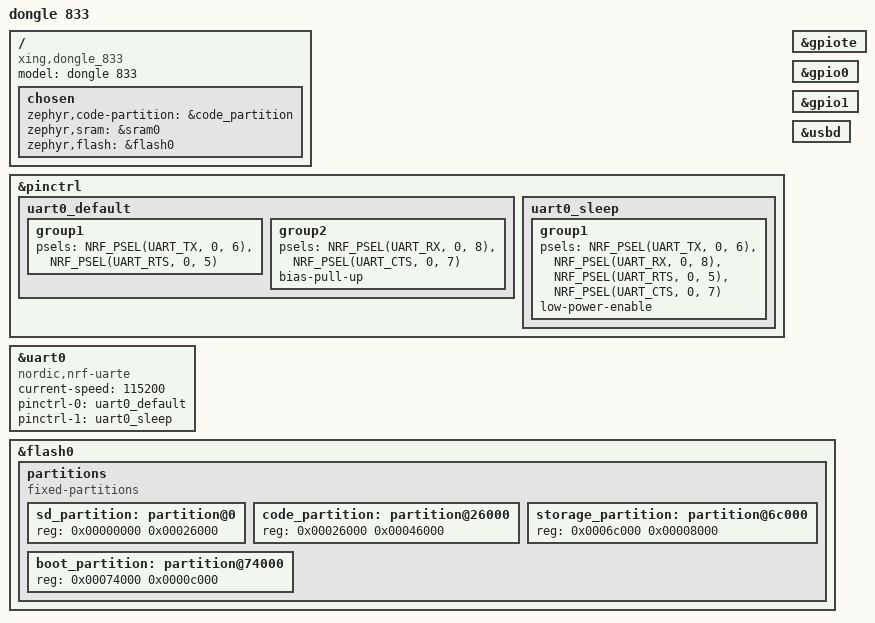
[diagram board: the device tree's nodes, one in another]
/*
 * Copyright (c) 2020 The ZMK Contributors
 *
 * SPDX-License-Identifier: MIT
 */

/dts-v1/;
#include <nordic/nrf52833_qiaa.dtsi>
#include "arduino_pro_micro_pins.dtsi"

&pinctrl {
	uart0_default: uart0_default {
		group1 {
			psels = <NRF_PSEL(UART_TX, 0, 6)>,
				<NRF_PSEL(UART_RTS, 0, 5)>;
		};
		group2 {
			psels = <NRF_PSEL(UART_RX, 0, 8)>,
				<NRF_PSEL(UART_CTS, 0, 7)>;
			bias-pull-up;
		};
	};

	uart0_sleep: uart0_sleep {
		group1 {
			psels = <NRF_PSEL(UART_TX, 0, 6)>,
				<NRF_PSEL(UART_RX, 0, 8)>,
				<NRF_PSEL(UART_RTS, 0, 5)>,
				<NRF_PSEL(UART_CTS, 0, 7)>;
			low-power-enable;
		};
	};
};

/ {
    model = "dongle 833";
    compatible = "xing,dongle_833";

    chosen {
        zephyr,code-partition = &code_partition;
        zephyr,sram = &sram0;
        zephyr,flash = &flash0;
    };

};



&gpiote {
    status = "okay";
};

&gpio0 {
    status = "okay";
};

&gpio1 {
    status = "okay";
};


&uart0 {
    compatible = "nordic,nrf-uarte";
    current-speed = <115200>;
    pinctrl-0 = <&uart0_default>;
    pinctrl-1 = <&uart0_sleep>;
    pinctrl-names = "default", "sleep";
};


zephyr_udc0: &usbd {
    status = "okay";
};

&flash0 {
    /*
     * For more information, see:
     * http://docs.zephyrproject.org/latest/devices/dts/flash_partitions.html
     */
    partitions {
        compatible = "fixed-partitions";
        #address-cells = <1>;
        #size-cells = <1>;

        sd_partition: partition@0 {
            reg = <0x00000000 0x00026000>;
        };
        code_partition: partition@26000 {
            reg = <0x00026000 0x00046000>;
        };

        /*
         * The flash starting at 0x000ec000 and ending at
         * 0x000f3fff is reserved for use by the application.
         */

        /*
         * Storage partition will be used by FCB/LittleFS/NVS
         * if enabled.
         */
        storage_partition: partition@6c000 {
            reg = <0x0006c000 0x00008000>;
        };

        boot_partition: partition@74000 {
            reg = <0x00074000 0x0000c000>;
        };
    };
};

